# STM32G07x register map
File version: 1.3
Registers are 32-bit, read-write, reset 0x0 unless marked. A register's access mark holds for its fields unless they carry their own. Offsets are from the block's base; [hi:lo] are bit positions; {n}, {i} and the like mark numbered series; 'fields as' and 'values as' point back to an identical list.

## AES — Advanced encryption standard hardware accelerator 1
Base 0x40026000
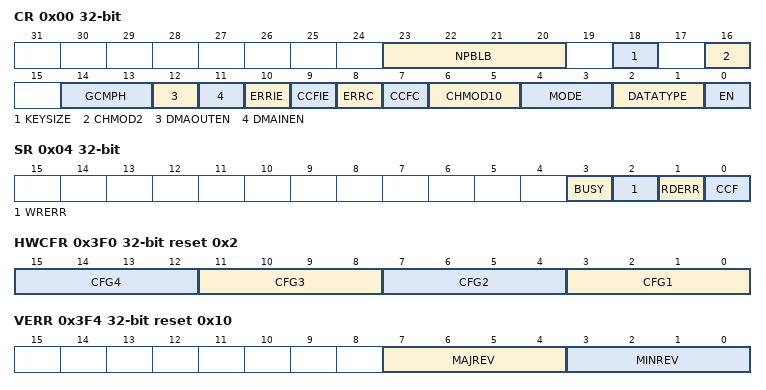
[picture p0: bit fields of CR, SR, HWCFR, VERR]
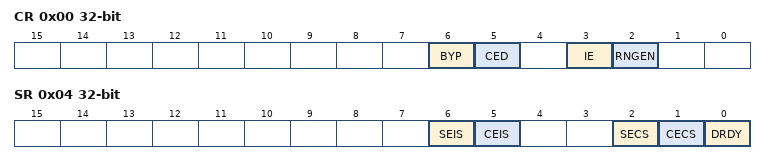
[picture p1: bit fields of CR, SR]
0x00 CR — control register
  [23:20] NPBLB — Number of padding bytes in last block of payload
  [18] KEYSIZE — Key size selection
  [16] CHMOD2 — AES chaining mode Bit2
  [14:13] GCMPH — Used only for GCM, CCM and GMAC algorithms and has no effect when other algorithms are selected
  [12] DMAOUTEN — Enable DMA management of data output phase
  [11] DMAINEN — Enable DMA management of data input phase
  [10] ERRIE — Error interrupt enable
  [9] CCFIE — CCF flag interrupt enable
  [8] ERRC — Error clear
  [7] CCFC — Computation Complete Flag Clear
  [6:5] CHMOD10 — AES chaining mode Bit1 Bit0
  [4:3] MODE — AES operating mode
  [2:1] DATATYPE — Data type selection (for data in and data out to/from the cryptographic block)
  [0] EN — AES enable
0x04 SR ro — status register
  [3] BUSY — Busy flag
  [2] WRERR — Write error flag
  [1] RDERR — Read error flag
  [0] CCF — Computation complete flag
0x08 DINR — data input register
  [31:0] AES_DINR — Data Input Register
0x0C DOUTR ro — data output register
  [31:0] AES_DOUTR — Data output register
0x10 KEYR0 — key register 0
  [31:0] AES_KEYR0 — Data Output Register (LSB key [31:0])
0x14 KEYR1 — key register 1
  [31:0] AES_KEYR1 — AES key register (key [63:32])
0x18 KEYR2 — key register 2
  [31:0] AES_KEYR2 — AES key register (key [95:64])
0x1C KEYR3 — key register 3
  [31:0] AES_KEYR3 — AES key register (MSB key [127:96])
0x20 IVR0 — initialization vector register 0
  [31:0] AES_IVR0 — initialization vector register (LSB IVR [31:0])
0x24 IVR1 — initialization vector register 1
  [31:0] AES_IVR1 — Initialization Vector Register (IVR [63:32])
0x28 IVR2 — initialization vector register 2
  [31:0] AES_IVR2 — Initialization Vector Register (IVR [95:64])
0x2C IVR3 — initialization vector register 3
  [31:0] AES_IVR3 — Initialization Vector Register (MSB IVR [127:96])
{0x20+4i} KEYR{i} (i=4..7) — key register {i}
  [31:0] AES_KEYR{i} — AES key register (MSB key [{32i+31}:{32i}])
{0x40+4i} SUSP{i}R (i=0..7) — AES suspend register {i}
  [31:0] AES_SUSP{i}R
0x3F0 HWCFR ro reset 0x2 — AES hardware configuration register
  [4n-1:4n-4] CFG{n} (n=1..4) — HW Generic {n}
0x3F4 VERR ro reset 0x10 — AES version register
  [7:4] MAJREV — Major revision
  [3:0] MINREV — Minor revision
0x3F8 IPIDR ro reset 0x170023 — AES identification register
  [31:0] ID — Identification code
0x3FC SIDR ro reset 0x170023 — AES size ID register
  [31:0] ID — Size Identification code

## RNG — Random number generator
Base 0x40025000
0x00 CR — control register
  [6] BYP — Bypass mode enable
  [5] CED — Clock error detection
  [3] IE — Interrupt enable
  [2] RNGEN — Random number generator enable
0x04 SR access per field — status register
  [6] SEIS rw — Seed error interrupt status
  [5] CEIS rw — Clock error interrupt status
  [2] SECS ro — Seed error current status
  [1] CECS ro — Clock error current status
  [0] DRDY ro — Data ready
0x08 DR ro — data register
  [31:0] RNDATA — Random data

## CRC — Cyclic redundancy check calculation unit
Base 0x40023000
0x00 DR reset 0xFFFFFFFF — Data register
  [31:0] DR — Data register bits
0x04 IDR — Independent data register
  [31:0] IDR — General-purpose 32-bit data register bits
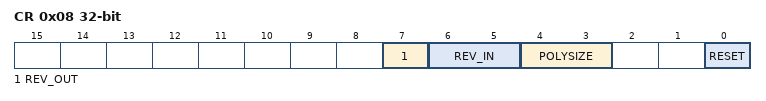
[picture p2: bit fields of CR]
0x08 CR access per field — Control register
  [7] REV_OUT rw — Reverse output data
  [6:5] REV_IN rw — Reverse input data
  [4:3] POLYSIZE rw — Polynomial size
  [0] RESET wo — RESET bit
0x10 INIT reset 0xFFFFFFFF — Initial CRC value
  [31:0] CRC_INIT — Programmable initial CRC value
0x14 POL reset 0x4C11DB7 — polynomial
  [31:0] POL — Programmable polynomial

## EXTI — External interrupt/event controller
Base 0x40021800
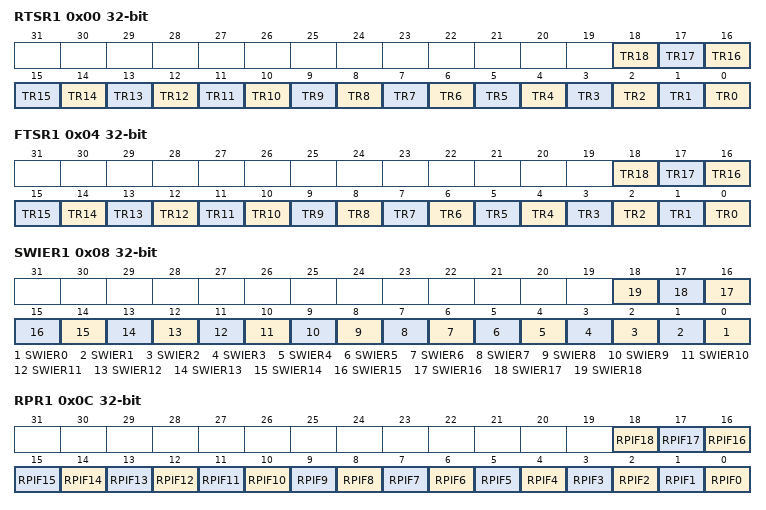
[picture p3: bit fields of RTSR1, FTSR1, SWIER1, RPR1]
0x00 RTSR1 — EXTI rising trigger selection register
  [n] TR{n} (n=0..18) — Rising trigger event configuration bit of Configurable Event input
0x04 FTSR1 — EXTI falling trigger selection register
  fields as RTSR1
0x08 SWIER1 — EXTI software interrupt event register
  [n] SWIER{n} (n=0..18) — Rising trigger event configuration bit of Configurable Event input
0x0C RPR1 — EXTI rising edge pending register
  [n] RPIF{n} (n=6..18) — configurable event inputs x rising edge Pending bit.
  [5] RPIF5 — configurable event inputs x rising edge Pending bit
  [n] RPIF{n} (n=0..4) — configurable event inputs x rising edge Pending bit.
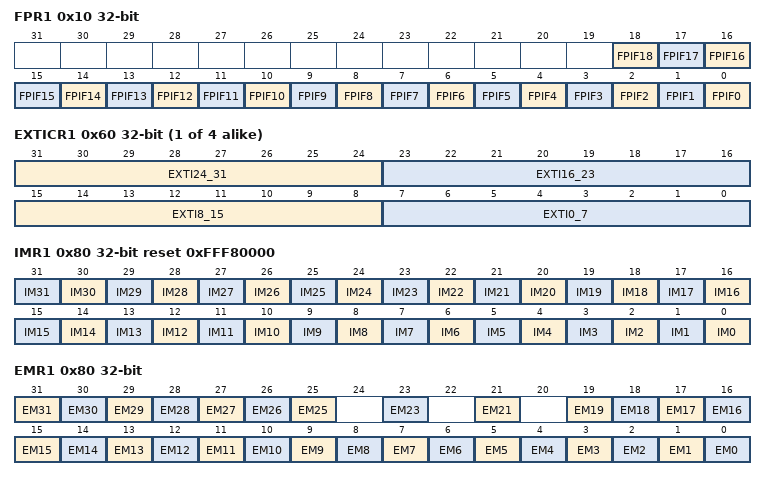
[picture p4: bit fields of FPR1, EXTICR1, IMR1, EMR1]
0x10 FPR1 — EXTI falling edge pending register
  [n] FPIF{n} (n=0..18) — configurable event inputs x falling edge pending bit.
{0x5C+4i} EXTICR{i} (i=1..4) — EXTI external interrupt selection register
  [31:24] EXTI24_31 — GPIO port selection
  [23:16] EXTI16_23 — GPIO port selection
  [15:8] EXTI8_15 — GPIO port selection
  [7:0] EXTI0_7 — GPIO port selection
0x80 IMR1 reset 0xFFF80000 — EXTI CPU wakeup with interrupt mask register
  [n] IM{n} (n=0..31) — CPU wakeup with interrupt mask on event input
0x80 EMR1 (alternate view of IMR1) — EXTI CPU wakeup with event mask register
  [n] EM{n} (n=25..31) — CPU wakeup with event mask on event input
  [23] EM23 — CPU wakeup with event mask on event input
  [21] EM21 — CPU wakeup with event mask on event input
  [n] EM{n} (n=0..19) — CPU wakeup with event mask on event input
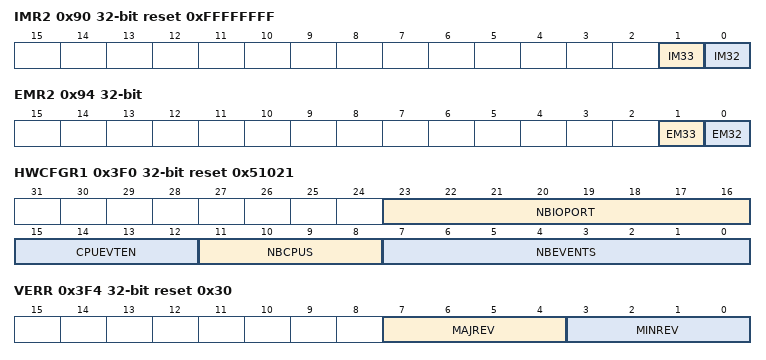
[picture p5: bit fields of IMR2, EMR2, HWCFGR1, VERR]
0x90 IMR2 reset 0xFFFFFFFF — EXTI CPU wakeup with interrupt mask register
  [1] IM33 — CPU wakeup with interrupt mask on event input
  [0] IM32 — CPU wakeup with interrupt mask on event input
0x94 EMR2 — EXTI CPU wakeup with event mask register
  [1] EM33 — CPU wakeup with event mask on event input
  [0] EM32 — CPU wakeup with event mask on event input
0x3D8 HWCFGR7 — Hardware configuration registers
  [31:0] CPUEVENT — HW configuration CPU event generation
0x3DC HWCFGR6 reset 0x3 — Hardware configuration registers
  [31:0] CPUEVENT — HW configuration CPU event generation
0x3E0 HWCFGR5 reset 0xFEAFFFFF — Hardware configuration registers
  [31:0] CPUEVENT — HW configuration CPU event generation
0x3E4 HWCFGR4 — Hardware configuration registers
  [31:0] EVENT_TRG — HW configuration event trigger type
0x3E8 HWCFGR3 — Hardware configuration registers
  [31:0] EVENT_TRG — HW configuration event trigger type
0x3EC HWCFGR2 reset 0x7FFFF — Hardware configuration registers
  [31:0] EVENT_TRG — HW configuration event trigger type
0x3F0 HWCFGR1 ro reset 0x51021 — Hardware configuration registers
  [23:16] NBIOPORT — HW configuration of number of IO ports
  [15:12] CPUEVTEN — HW configuration of CPU event output enable
  [11:8] NBCPUS — configuration number of CPUs
  [7:0] NBEVENTS — configuration number of event
0x3F4 VERR ro reset 0x30 — AES version register
  [7:4] MAJREV — Major revision
  [3:0] MINREV — Minor revision
0x3F8 IPIDR ro reset 0xE0001 — AES identification register
  [31:0] ID — Identification code
0x3FC SIDR ro reset 0xA3C5DD01 — AES size ID register
  [31:0] ID — Size Identification code
